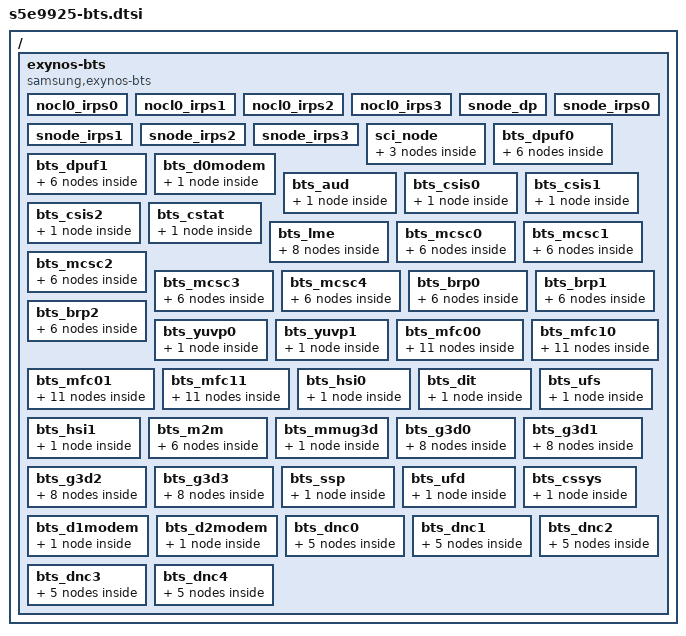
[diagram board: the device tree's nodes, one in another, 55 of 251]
/*
 * SAMSUNG EXYNOS SoC BTS device tree source
 *
 * Copyright (c) 2018 Samsung Electronics Co., Ltd.
 *		http://www.samsung.com
 *
 * SAMSUNG EXYNOS SoC BTS device nodes are listed in this file.
 * EXYNOS based board files should include this file.
 *
 * This program is free software; you can redistribute it and/or modify
 * it under the terms of the GNU General Public License version 2 as
 * published by the Free Software Foundation.
 *
 */

#include <dt-bindings/soc/samsung/exynos-bts.h>


/ {
	exynos-bts {
		compatible = "samsung,exynos-bts";
		#address-cells = <2>;
		#size-cells = <1>;
		ranges;

		list-scen = "default",
			"cp_throughput",
			"mfc_uhd",
			"mfc_uhd_10bit",
			"mfc_8k_dec30",
			"gdc_8k_8b_30",
			"gdc_8k_8b_60",
			"g3d_heavy",
			"g3d_performance",
			"dp_default",
			"camera_default",
			"npu_normal",
			"mfc_uhd_enc60",
			"camera_heavy",
			"npu_performance";

	        /* num_channel, mif_bus_width, bus_width, mif_util, int_util*/
	        bw_params = <4 16 32 65 70>;

		/* IRPS0/1/2/3 SCI_CTL_SCI_CTRL*/
		nocl0_irps0 {
			#address-cells = <2>;
			#size-cells = <1>;
			ranges;
			reg = <0x0 0x1A904000 0x400>;
			status = "okay";
			bts-type = <TREX_BTS>;
		};
		nocl0_irps1 {
			reg = <0x0 0x1A914000 0x400>;
			status = "okay";
			bts-type = <TREX_BTS>;
		};
		nocl0_irps2 {
			reg = <0x0 0x1A924000 0x400>;
			status = "okay";
			bts-type = <TREX_BTS>;
		};
		nocl0_irps3 {
			reg = <0x0 0x1A934000 0x400>;
			status = "okay";
			bts-type = <TREX_BTS>;
		};
		/* QMAX THRESHOLD */
		snode_dp {
			reg = <0x0 0x1A942000 0x100>;
			status = "okay";
			bts-type = <BUSC_BTS>;
		};
		snode_irps0 {
			reg = <0x0 0x1A902000 0x100>;
			status = "okay";
			bts-type = <BUSC_BTS>;
		};
		snode_irps1 {
			reg = <0x0 0x1A912000 0x100>;
			status = "okay";
			bts-type = <BUSC_BTS>;
		};
		snode_irps2 {
			reg = <0x0 0x1A922000 0x100>;
			status = "okay";
			bts-type = <BUSC_BTS>;
		};
		snode_irps3 {
			reg = <0x0 0x1A932000 0x100>;
			status = "okay";
			bts-type = <BUSC_BTS>;
		};
		sci_node {
			reg = <0x0 0x1A000100 0x100>;
			status = "okay";
			bts-type = <SCI_BTS>;
			default {
				stat_on = <1>;
				rmo = <0x0>;
				wmo = <0x0>;
			};
			camera_default {
				stat_on = <1>;
				rmo = <0x8>;
				wmo = <0x8>;
			};
			camera_heavy {
				stat_on = <1>;
				rmo = <0x8>;
				wmo = <0x8>;
			};
		};
		/* NOCL1A D0_DPUF0 */
		bts_dpuf0 {
			reg = <0x0 0x1B2A0000 0x100>;
			status = "okay";
			bts-type = <IP_BTS>;
			default {
				stat_on = <1>;
				bypass = <0>;
				arqos = <0x8>;
				awqos = <0x8>;
				qurgent_on = <0xC>;
				qurgent_th_r = <0x14>;
				blocking_on = <0>;
			};
			camera_default {
				stat_on = <1>;
				bypass = <0>;
				arqos = <0x8>;
				awqos = <0x8>;
				rmo = <0x20>;
				wmo = <0x20>;
				qurgent_on = <0>;
				blocking_on = <0>;
			};
			npu_normal {
				stat_on = <1>;
				bypass = <0>;
				arqos = <0x8>;
				awqos = <0x8>;
				rmo = <0x20>;
				wmo = <0x20>;
				qurgent_on = <0>;
				blocking_on = <0>;
			};
			mfc_uhd_enc60 {
				stat_on = <1>;
				bypass = <0>;
				arqos = <0x8>;
				awqos = <0x8>;
				rmo = <0x20>;
				wmo = <0x20>;
				qurgent_on = <0>;
				blocking_on = <0>;
			};
			camera_heavy {
				stat_on = <1>;
				bypass = <0>;
				arqos = <0x8>;
				awqos = <0x8>;
				rmo = <0x20>;
				wmo = <0x20>;
				qurgent_on = <0>;
				blocking_on = <0>;
			};
			npu_performance {
				stat_on = <1>;
				bypass = <0>;
				arqos = <0x8>;
				awqos = <0x8>;
				rmo = <0x20>;
				wmo = <0x20>;
				qurgent_on = <0>;
				blocking_on = <0>;
			};
		};
		/* NOCL1A D1_DPUF0 */
		bts_dpuf1 {
			reg = <0x0 0x1B2B0000 0x100>;
			status = "okay";
			bts-type = <IP_BTS>;
			default {
				stat_on = <1>;
				bypass = <0>;
				arqos = <0x8>;
				awqos = <0x8>;
				qurgent_on = <0xC>;
				qurgent_th_r = <0x14>;
				blocking_on = <0>;
			};
			camera_default {
				stat_on = <1>;
				bypass = <0>;
				arqos = <0x8>;
				awqos = <0x8>;
				rmo = <0x20>;
				wmo = <0x20>;
				qurgent_on = <0>;
				blocking_on = <0>;
			};
			npu_normal {
				stat_on = <1>;
				bypass = <0>;
				arqos = <0x8>;
				awqos = <0x8>;
				rmo = <0x20>;
				wmo = <0x20>;
				qurgent_on = <0>;
				blocking_on = <0>;
			};
			mfc_uhd_enc60 {
				stat_on = <1>;
				bypass = <0>;
				arqos = <0x8>;
				awqos = <0x8>;
				rmo = <0x20>;
				wmo = <0x20>;
				qurgent_on = <0>;
				blocking_on = <0>;
			};
			camera_heavy {
				stat_on = <1>;
				bypass = <0>;
				arqos = <0x8>;
				awqos = <0x8>;
				rmo = <0x20>;
				wmo = <0x20>;
				qurgent_on = <0>;
				blocking_on = <0>;
			};
			npu_performance {
				stat_on = <1>;
				bypass = <0>;
				arqos = <0x8>;
				awqos = <0x8>;
				rmo = <0x20>;
				wmo = <0x20>;
				qurgent_on = <0>;
				blocking_on = <0>;
			};
		};
		/* NOCL0 D0_MODEM */
		bts_d0modem {
			reg = <0x0 0x1A890000 0x100>;
			status = "okay";
			bts-type = <IP_BTS>;
			default {
				stat_on = <1>;
				bypass = <0>;
				arqos = <0xD>;
				awqos = <0xD>;
				rmo = <0x20>;
				wmo = <0x20>;
				qurgent_on = <0xC>;
				qurgent_th_r = <0x14>;
				qurgent_th_w = <0x14>;
				blocking_on = <0>;
			};
		};
		/* NOCL0 AUD */
		bts_aud {
			reg = <0x0 0x1A8C0000 0x100>;
			status = "okay";
			bts-type = <IP_BTS>;
			default {
				stat_on = <1>;
				bypass = <0>;
				arqos = <0x9>;
				awqos = <0x9>;
				qurgent_on = <0xC>;
				qurgent_th_r = <0x14>;
				qurgent_th_w = <0x14>;
				blocking_on = <0>;
			};
		};
		/* NOCL1C D0_CSIS */
		bts_csis0 {
			reg = <0x0 0x1B400000 0x100>;
			status = "okay";
			bts-type = <IP_BTS>;
			cal-pdid = <0xB1380002>;
			default {
				stat_on = <1>;
				bypass = <0>;
				arqos = <0xC>;
				awqos = <0xC>;
				qurgent_on = <0xC>;
				qurgent_th_r = <0x14>;
				qurgent_th_w = <0xD>;
				blocking_on = <0>;
			};
		};
		/* NOCL1C D1_CSIS */
		bts_csis1 {
			reg = <0x0 0x1B410000 0x100>;
			status = "okay";
			bts-type = <IP_BTS>;
			cal-pdid = <0xB1380002>;
			default {
				stat_on = <1>;
				bypass = <0>;
				arqos = <0xC>;
				awqos = <0xC>;
				qurgent_on = <0xC>;
				qurgent_th_r = <0x14>;
				qurgent_th_w = <0xD>;
				blocking_on = <0>;
			};
		};
		/* NOCL1C D2_CSIS */
		bts_csis2 {
			reg = <0x0 0x1B420000 0x100>;
			status = "okay";
			bts-type = <IP_BTS>;
			cal-pdid = <0xB1380002>;
			default {
				stat_on = <1>;
				bypass = <0>;
				arqos = <0xC>;
				awqos = <0xC>;
				qurgent_on = <0xC>;
				qurgent_th_r = <0x14>;
				qurgent_th_w = <0xD>;
				blocking_on = <0>;
			};
		};
		/* NOCL1C CSTAT */
		bts_cstat {
			reg = <0x0 0x1B430000 0x100>;
			status = "okay";
			bts-type = <IP_BTS>;
			cal-pdid = <0xB1380002>;
			default {
				stat_on = <1>;
				bypass = <0>;
				arqos = <0xC>;
				awqos = <0xC>;
				qurgent_on = <0xC>;
				qurgent_th_r = <0x14>;
				qurgent_th_w = <0xD>;
				blocking_on = <0>;
			};
		};
		/* NOCL1A LME */
		bts_lme {
			reg = <0x0 0x1B250000 0x100>;
			status = "okay";
			bts-type = <IP_BTS>;
			default {
				stat_on = <1>;
				bypass = <0>;
				arqos = <0x4>;
				awqos = <0x4>;
				rmo = <0x4>;
				wmo = <0x8>;
				qurgent_on = <0>;
				blocking_on = <0>;
			};
			gdc_8k_8b_30 {
				stat_on = <1>;
				bypass = <0>;
				arqos = <0x4>;
				awqos = <0x4>;
				rmo = <0x3C>;
				wmo = <0x14>;
				qurgent_on = <0>;
				blocking_on = <0>;
			};
			gdc_8k_8b_60 {
				stat_on = <1>;
				bypass = <0>;
				arqos = <0x4>;
				awqos = <0x4>;
				rmo = <0x84>;
				wmo = <0x28>;
				qurgent_on = <0>;
				blocking_on = <0>;
			};
			camera_default {
				stat_on = <1>;
				bypass = <0>;
				arqos = <0x4>;
				awqos = <0x4>;
				rmo = <0x28>;
				wmo = <0x8>;
				qurgent_on = <0>;
				blocking_on = <0>;
			};
			npu_normal {
				stat_on = <1>;
				bypass = <0>;
				arqos = <0x4>;
				awqos = <0x4>;
				rmo = <0x28>;
				wmo = <0x8>;
				qurgent_on = <0>;
				blocking_on = <0>;
			};
			mfc_uhd_enc60 {
				stat_on = <1>;
				bypass = <0>;
				arqos = <0x4>;
				awqos = <0x4>;
				rmo = <0x4>;
				wmo = <0x8>;
				qurgent_on = <0>;
				blocking_on = <0>;
			};
			camera_heavy {
				stat_on = <1>;
				bypass = <0>;
				arqos = <0x4>;
				awqos = <0x4>;
				rmo = <0x28>;
				wmo = <0x8>;
				qurgent_on = <0>;
				blocking_on = <0>;
			};
			npu_performance {
				stat_on = <1>;
				bypass = <0>;
				arqos = <0x4>;
				awqos = <0x4>;
				rmo = <0x4>;
				wmo = <0x8>;
				qurgent_on = <0>;
				blocking_on = <0>;
			};
		};
		/* NOCL1C D0_MCSC */
		bts_mcsc0 {
			reg = <0x0 0x1B470000 0x100>;
			status = "okay";
			bts-type = <IP_BTS>;
			cal-pdid = <0xB1380002>;
			default {
				stat_on = <1>;
				bypass = <0>;
				arqos = <0x4>;
				awqos = <0x4>;
				rmo = <0x8>;
				wmo = <0x8>;
				qurgent_on = <0>;
				blocking_on = <0>;
			};
			camera_default {
				stat_on = <1>;
				bypass = <0>;
				arqos = <0x4>;
				awqos = <0x4>;
				rmo = <0x10>;
				wmo = <0x8>;
				qurgent_on = <0>;
				blocking_on = <0>;
			};
			npu_normal {
				stat_on = <1>;
				bypass = <0>;
				arqos = <0x4>;
				awqos = <0x4>;
				rmo = <0x10>;
				wmo = <0x8>;
				qurgent_on = <0>;
				blocking_on = <0>;
			};
			mfc_uhd_enc60 {
				stat_on = <1>;
				bypass = <0>;
				arqos = <0x4>;
				awqos = <0x4>;
				rmo = <0x8>;
				wmo = <0x8>;
				qurgent_on = <0>;
				blocking_on = <0>;
			};
			camera_heavy {
				stat_on = <1>;
				bypass = <0>;
				arqos = <0x4>;
				awqos = <0x4>;
				rmo = <0x20>;
				wmo = <0x20>;
				qurgent_on = <0>;
				blocking_on = <0>;
			};
			npu_performance {
				stat_on = <1>;
				bypass = <0>;
				arqos = <0x4>;
				awqos = <0x4>;
				rmo = <0x8>;
				wmo = <0x8>;
				qurgent_on = <0>;
				blocking_on = <0>;
			};
		};
		/* NOCL1C D1_MCSC */
		bts_mcsc1 {
			reg = <0x0 0x1B480000 0x100>;
			status = "okay";
			bts-type = <IP_BTS>;
			cal-pdid = <0xB1380002>;
			default {
				stat_on = <1>;
				bypass = <0>;
				arqos = <0x4>;
				awqos = <0x4>;
				rmo = <0x8>;
				wmo = <0x8>;
				qurgent_on = <0>;
				blocking_on = <0>;
			};
			camera_default {
				stat_on = <1>;
				bypass = <0>;
				arqos = <0x4>;
				awqos = <0x4>;
				rmo = <0x10>;
				wmo = <0x10>;
				qurgent_on = <0>;
				blocking_on = <0>;
			};
			npu_normal {
				stat_on = <1>;
				bypass = <0>;
				arqos = <0x4>;
				awqos = <0x4>;
				rmo = <0x10>;
				wmo = <0x10>;
				qurgent_on = <0>;
				blocking_on = <0>;
			};
			mfc_uhd_enc60 {
				stat_on = <1>;
				bypass = <0>;
				arqos = <0x4>;
				awqos = <0x4>;
				rmo = <0x8>;
				wmo = <0x8>;
				qurgent_on = <0>;
				blocking_on = <0>;
			};
			camera_heavy {
				stat_on = <1>;
				bypass = <0>;
				arqos = <0x4>;
				awqos = <0x4>;
				rmo = <0x20>;
				wmo = <0x20>;
				qurgent_on = <0>;
				blocking_on = <0>;
			};
			npu_performance {
				stat_on = <1>;
				bypass = <0>;
				arqos = <0x4>;
				awqos = <0x4>;
				rmo = <0x8>;
				wmo = <0x8>;
				qurgent_on = <0>;
				blocking_on = <0>;
			};
		};
		/* NOCL1C D2_MCSC */
		bts_mcsc2 {
			reg = <0x0 0x1B490000 0x100>;
			status = "okay";
			bts-type = <IP_BTS>;
			cal-pdid = <0xB1380002>;
			default {
				stat_on = <1>;
				bypass = <0>;
				arqos = <0x4>;
				awqos = <0x4>;
				rmo = <0x8>;
				wmo = <0x8>;
				qurgent_on = <0>;
				blocking_on = <0>;
			};
			camera_default {
				stat_on = <1>;
				bypass = <0>;
				arqos = <0x4>;
				awqos = <0x4>;
				rmo = <0x10>;
				wmo = <0x10>;
				qurgent_on = <0>;
				blocking_on = <0>;
			};
			npu_normal {
				stat_on = <1>;
				bypass = <0>;
				arqos = <0x4>;
				awqos = <0x4>;
				rmo = <0x10>;
				wmo = <0x10>;
				qurgent_on = <0>;
				blocking_on = <0>;
			};
			mfc_uhd_enc60 {
				stat_on = <1>;
				bypass = <0>;
				arqos = <0x4>;
				awqos = <0x4>;
				rmo = <0x8>;
				wmo = <0x8>;
				qurgent_on = <0>;
				blocking_on = <0>;
			};
			camera_heavy {
				stat_on = <1>;
				bypass = <0>;
				arqos = <0x4>;
				awqos = <0x4>;
				rmo = <0x20>;
				wmo = <0x20>;
				qurgent_on = <0>;
				blocking_on = <0>;
			};
			npu_performance {
				stat_on = <1>;
				bypass = <0>;
				arqos = <0x4>;
				awqos = <0x4>;
				rmo = <0x8>;
				wmo = <0x8>;
				qurgent_on = <0>;
				blocking_on = <0>;
			};
		};
		/* NOCL1C D3_MCSC */
		bts_mcsc3 {
			reg = <0x0 0x1B4A0000 0x100>;
			status = "okay";
			bts-type = <IP_BTS>;
			cal-pdid = <0xB1380002>;
			default {
				stat_on = <1>;
				bypass = <0>;
				arqos = <0x4>;
				awqos = <0x4>;
				rmo = <0x8>;
				wmo = <0x8>;
				qurgent_on = <0>;
				blocking_on = <0>;
			};
			camera_default {
				stat_on = <1>;
				bypass = <0>;
				arqos = <0x4>;
				awqos = <0x4>;
				rmo = <0x10>;
				wmo = <0x10>;
				qurgent_on = <0>;
				blocking_on = <0>;
			};
			npu_normal {
				stat_on = <1>;
				bypass = <0>;
				arqos = <0x4>;
				awqos = <0x4>;
				rmo = <0x10>;
				wmo = <0x10>;
				qurgent_on = <0>;
				blocking_on = <0>;
			};
			mfc_uhd_enc60 {
				stat_on = <1>;
				bypass = <0>;
				arqos = <0x4>;
				awqos = <0x4>;
				rmo = <0x8>;
				wmo = <0x8>;
				qurgent_on = <0>;
				blocking_on = <0>;
			};
			camera_heavy {
				stat_on = <1>;
				bypass = <0>;
				arqos = <0x4>;
				awqos = <0x4>;
				rmo = <0x20>;
				wmo = <0x20>;
				qurgent_on = <0>;
				blocking_on = <0>;
			};
			npu_performance {
				stat_on = <1>;
				bypass = <0>;
				arqos = <0x4>;
				awqos = <0x4>;
				rmo = <0x8>;
				wmo = <0x8>;
				qurgent_on = <0>;
				blocking_on = <0>;
			};
		};
		/* NOCL1C D4_MCSC */
		bts_mcsc4 {
			reg = <0x0 0x1B4B0000 0x100>;
			status = "okay";
			bts-type = <IP_BTS>;
			cal-pdid = <0xB1380002>;
			default {
				stat_on = <1>;
				bypass = <0>;
				arqos = <0x4>;
				awqos = <0x4>;
				rmo = <0x8>;
				wmo = <0x8>;
				qurgent_on = <0>;
				blocking_on = <0>;
			};
			camera_default {
				stat_on = <1>;
				bypass = <0>;
				arqos = <0x4>;
				awqos = <0x4>;
				rmo = <0x10>;
				wmo = <0x10>;
				qurgent_on = <0>;
				blocking_on = <0>;
			};
			npu_normal {
				stat_on = <1>;
				bypass = <0>;
				arqos = <0x4>;
				awqos = <0x4>;
				rmo = <0x10>;
				wmo = <0x10>;
				qurgent_on = <0>;
				blocking_on = <0>;
			};
			mfc_uhd_enc60 {
				stat_on = <1>;
				bypass = <0>;
				arqos = <0x4>;
				awqos = <0x4>;
				rmo = <0x8>;
				wmo = <0x8>;
				qurgent_on = <0>;
				blocking_on = <0>;
			};
			camera_heavy {
				stat_on = <1>;
				bypass = <0>;
				arqos = <0x4>;
				awqos = <0x4>;
				rmo = <0x20>;
				wmo = <0x20>;
				qurgent_on = <0>;
				blocking_on = <0>;
			};
			npu_performance {
				stat_on = <1>;
				bypass = <0>;
				arqos = <0x4>;
				awqos = <0x4>;
				rmo = <0x8>;
				wmo = <0x8>;
				qurgent_on = <0>;
				blocking_on = <0>;
			};
		};
		/* NOCL1C D0_BRP */
		bts_brp0 {
			reg = <0x0 0x1B440000 0x100>;
			status = "okay";
			bts-type = <IP_BTS>;
			cal-pdid = <0xB1380002>;
			default {
				stat_on = <1>;
				bypass = <0>;
				arqos = <0x4>;
				awqos = <0x4>;
				rmo = <0x4>;
				wmo = <0x8>;
				qurgent_on = <0>;
				blocking_on = <0>;
			};
			camera_default {
				stat_on = <1>;
				bypass = <0>;
				arqos = <0x4>;
				awqos = <0x4>;
				rmo = <0x10>;
				wmo = <0x8>;
				qurgent_on = <0>;
				blocking_on = <0>;
			};
			npu_normal {
				stat_on = <1>;
				bypass = <0>;
				arqos = <0x4>;
				awqos = <0x4>;
				rmo = <0x10>;
				wmo = <0x8>;
				qurgent_on = <0>;
				blocking_on = <0>;
			};
			mfc_uhd_enc60 {
				stat_on = <1>;
				bypass = <0>;
				arqos = <0x4>;
				awqos = <0x4>;
				rmo = <0x4>;
				wmo = <0x8>;
				qurgent_on = <0>;
				blocking_on = <0>;
			};
			camera_heavy {
				stat_on = <1>;
				bypass = <0>;
				arqos = <0x4>;
				awqos = <0x4>;
				rmo = <0x20>;
				wmo = <0x20>;
				qurgent_on = <0>;
				blocking_on = <0>;
			};
			npu_performance {
				stat_on = <1>;
				bypass = <0>;
				arqos = <0x4>;
				awqos = <0x4>;
				rmo = <0x4>;
				wmo = <0x8>;
				qurgent_on = <0>;
				blocking_on = <0>;
			};

		};
		/* NOCL1C D1_BRP */
		bts_brp1 {
			reg = <0x0 0x1B450000 0x100>;
			status = "okay";
			bts-type = <IP_BTS>;
			cal-pdid = <0xB1380002>;
			default {
				stat_on = <1>;
				bypass = <0>;
				arqos = <0x4>;
				awqos = <0x4>;
				rmo = <0x4>;
				wmo = <0x8>;
				qurgent_on = <0>;
				blocking_on = <0>;
			};
			camera_default {
				stat_on = <1>;
				bypass = <0>;
				arqos = <0x4>;
				awqos = <0x4>;
				rmo = <0x10>;
				wmo = <0x8>;
				qurgent_on = <0>;
				blocking_on = <0>;
			};
			npu_normal {
				stat_on = <1>;
				bypass = <0>;
				arqos = <0x4>;
				awqos = <0x4>;
				rmo = <0x10>;
				wmo = <0x8>;
				qurgent_on = <0>;
				blocking_on = <0>;
			};
			mfc_uhd_enc60 {
				stat_on = <1>;
				bypass = <0>;
				arqos = <0x4>;
				awqos = <0x4>;
				rmo = <0x4>;
				wmo = <0x8>;
				qurgent_on = <0>;
				blocking_on = <0>;
			};
			camera_heavy {
				stat_on = <1>;
				bypass = <0>;
				arqos = <0x4>;
				awqos = <0x4>;
				rmo = <0x20>;
				wmo = <0x20>;
				qurgent_on = <0>;
				blocking_on = <0>;
			};
			npu_performance {
				stat_on = <1>;
				bypass = <0>;
				arqos = <0x4>;
				awqos = <0x4>;
				rmo = <0x4>;
				wmo = <0x8>;
				qurgent_on = <0>;
				blocking_on = <0>;
			};

		};
		/* NOCL1C D2_BRP */
		bts_brp2 {
			reg = <0x0 0x1B460000 0x100>;
			status = "okay";
			bts-type = <IP_BTS>;
			cal-pdid = <0xB1380002>;
			default {
				stat_on = <1>;
				bypass = <0>;
				arqos = <0x4>;
				awqos = <0x4>;
				rmo = <0x4>;
				wmo = <0x8>;
				qurgent_on = <0>;
				blocking_on = <0>;
			};
			camera_default {
				stat_on = <1>;
				bypass = <0>;
				arqos = <0x4>;
				awqos = <0x4>;
				rmo = <0x10>;
				wmo = <0x8>;
				qurgent_on = <0>;
				blocking_on = <0>;
			};
			npu_normal {
				stat_on = <1>;
				bypass = <0>;
				arqos = <0x4>;
				awqos = <0x4>;
				rmo = <0x10>;
				wmo = <0x8>;
				qurgent_on = <0>;
				blocking_on = <0>;
			};
			mfc_uhd_enc60 {
				stat_on = <1>;
				bypass = <0>;
				arqos = <0x4>;
				awqos = <0x4>;
				rmo = <0x4>;
				wmo = <0x8>;
				qurgent_on = <0>;
				blocking_on = <0>;
			};
			camera_heavy {
				stat_on = <1>;
				bypass = <0>;
				arqos = <0x4>;
				awqos = <0x4>;
				rmo = <0x20>;
				wmo = <0x20>;
				qurgent_on = <0>;
				blocking_on = <0>;
			};
			npu_performance {
				stat_on = <1>;
				bypass = <0>;
				arqos = <0x4>;
				awqos = <0x4>;
				rmo = <0x4>;
				wmo = <0x8>;
				qurgent_on = <0>;
				blocking_on = <0>;
			};

		};
		/* NOCL1C YUVP0 */
		bts_yuvp0 {
			reg = <0x0 0x1B4C0000 0x100>;
			status = "okay";
			bts-type = <IP_BTS>;
			cal-pdid = <0xB1380002>;
			default {
				stat_on = <1>;
				bypass = <0>;
				arqos = <0x4>;
				awqos = <0x4>;
				rmo = <0xC>;
				wmo = <0xC>;
				qurgent_on = <0>;
				blocking_on = <0>;
			};
		};
		/* NOCL1C YUVP1 */
		bts_yuvp1 {
			reg = <0x0 0x1B4D0000 0x100>;
			status = "okay";
			bts-type = <IP_BTS>;
			cal-pdid = <0xB1380002>;
			default {
				stat_on = <1>;
				bypass = <0>;
				arqos = <0x4>;
				awqos = <0x4>;
				rmo = <0xC>;
				wmo = <0xC>;
				qurgent_on = <0>;
				blocking_on = <0>;
			};
		};
		/* NOCL1A D0_MFC0 */
		bts_mfc00 {
			reg = <0x0 0x1B260000 0x100>;
			status = "okay";
			bts-type = <IP_BTS>;
			default {
				stat_on = <1>;
				bypass = <0>;
				arqos = <0x4>;
				awqos = <0x4>;
				rmo = <0x1C>;
				wmo = <0xC>;
				qurgent_on = <0>;
				blocking_on = <0>;
			};
			mfc_uhd {
				stat_on = <1>;
				bypass = <0>;
				arqos = <0x4>;
				awqos = <0x4>;
				rmo = <0x20>;
				wmo = <0x20>;
				qurgent_on = <0>;
				blocking_on = <0>;
			};
			mfc_uhd_10bit {
				stat_on = <1>;
				bypass = <0>;
				arqos = <0x4>;
				awqos = <0x4>;
				rmo = <0x20>;
				wmo = <0x20>;
				qurgent_on = <0>;
				blocking_on = <0>;
			};
			mfc_8k_dec30 {
				stat_on = <1>;
				bypass = <0>;
				arqos = <0x4>;
				awqos = <0x4>;
				rmo = <0x40>;
				wmo = <0x40>;
				qurgent_on = <0>;
				blocking_on = <0>;
			};
			g3d_performance {
				stat_on = <1>;
				bypass = <0>;
				arqos = <0x4>;
				awqos = <0x4>;
				rmo = <0x20>;
				wmo = <0x20>;
				qurgent_on = <0>;
				blocking_on = <0>;
			};
			dp_default {
				stat_on = <1>;
				bypass = <0>;
				arqos = <0x4>;
				awqos = <0x4>;
				rmo = <0x20>;
				wmo = <0x20>;
				qurgent_on = <0>;
				blocking_on = <0>;
			};
			camera_default {
				stat_on = <1>;
				bypass = <0>;
				arqos = <0x4>;
				awqos = <0x4>;
				rmo = <0x1C>;
				wmo = <0xC>;
				qurgent_on = <0>;
				blocking_on = <0>;
			};
			npu_normal {
				stat_on = <1>;
				bypass = <0>;
				arqos = <0x4>;
				awqos = <0x4>;
				rmo = <0x1C>;
				wmo = <0xC>;
				qurgent_on = <0>;
				blocking_on = <0>;
			};
			mfc_uhd_enc60 {
				stat_on = <1>;
				bypass = <0>;
				arqos = <0x4>;
				awqos = <0x4>;
				rmo = <0x20>;
				wmo = <0x20>;
				qurgent_on = <0>;
				blocking_on = <0>;
			};
			camera_heavy {
				stat_on = <1>;
				bypass = <0>;
				arqos = <0x4>;
				awqos = <0x4>;
				rmo = <0x1C>;
				wmo = <0xC>;
				qurgent_on = <0>;
				blocking_on = <0>;
			};
			npu_performance {
				stat_on = <1>;
				bypass = <0>;
				arqos = <0x4>;
				awqos = <0x4>;
				rmo = <0x1C>;
				wmo = <0xC>;
				qurgent_on = <0>;
				blocking_on = <0>;
			};
		};
		/* NOCL1A D0_MFC1 */
		bts_mfc10 {
			reg = <0x0 0x1B280000 0x100>;
			status = "okay";
			bts-type = <IP_BTS>;
			default {
				stat_on = <1>;
				bypass = <0>;
				arqos = <0x4>;
				awqos = <0x4>;
				rmo = <0x1C>;
				wmo = <0xC>;
				qurgent_on = <0>;
				blocking_on = <0>;
			};
			mfc_uhd {
				stat_on = <1>;
				bypass = <0>;
				arqos = <0x4>;
				awqos = <0x4>;
				rmo = <0x20>;
				wmo = <0x20>;
				qurgent_on = <0>;
				blocking_on = <0>;
			};
			mfc_uhd_10bit {
				stat_on = <1>;
				bypass = <0>;
				arqos = <0x4>;
				awqos = <0x4>;
				rmo = <0x20>;
				wmo = <0x20>;
				qurgent_on = <0>;
				blocking_on = <0>;
			};
			mfc_8k_dec30 {
				stat_on = <1>;
				bypass = <0>;
				arqos = <0x4>;
				awqos = <0x4>;
				rmo = <0x40>;
				wmo = <0x40>;
				qurgent_on = <0>;
				blocking_on = <0>;
			};
			g3d_performance {
				stat_on = <1>;
				bypass = <0>;
				arqos = <0x4>;
				awqos = <0x4>;
				rmo = <0x20>;
				wmo = <0x20>;
				qurgent_on = <0>;
				blocking_on = <0>;
			};
			dp_default {
				stat_on = <1>;
				bypass = <0>;
				arqos = <0x4>;
				awqos = <0x4>;
				rmo = <0x20>;
				wmo = <0x20>;
				qurgent_on = <0>;
				blocking_on = <0>;
			};
			camera_default {
				stat_on = <1>;
				bypass = <0>;
				arqos = <0x4>;
				awqos = <0x4>;
				rmo = <0x1C>;
				wmo = <0xC>;
				qurgent_on = <0>;
				blocking_on = <0>;
			};
			npu_normal {
				stat_on = <1>;
				bypass = <0>;
				arqos = <0x4>;
				awqos = <0x4>;
				rmo = <0x1C>;
				wmo = <0xC>;
				qurgent_on = <0>;
				blocking_on = <0>;
			};
			mfc_uhd_enc60 {
				stat_on = <1>;
				bypass = <0>;
				arqos = <0x4>;
				awqos = <0x4>;
				rmo = <0x20>;
				wmo = <0x20>;
				qurgent_on = <0>;
				blocking_on = <0>;
			};
			camera_heavy {
				stat_on = <1>;
				bypass = <0>;
				arqos = <0x4>;
				awqos = <0x4>;
				rmo = <0x1C>;
				wmo = <0xC>;
				qurgent_on = <0>;
				blocking_on = <0>;
			};
			npu_performance {
				stat_on = <1>;
				bypass = <0>;
				arqos = <0x4>;
				awqos = <0x4>;
				rmo = <0x1C>;
				wmo = <0xC>;
				qurgent_on = <0>;
				blocking_on = <0>;
			};
		};
		/* NOCL1A D1_MFC0 */
		bts_mfc01 {
			reg = <0x0 0x1B270000 0x100>;
			status = "okay";
			bts-type = <IP_BTS>;
			default {
				stat_on = <1>;
				bypass = <0>;
				arqos = <0x4>;
				awqos = <0x4>;
				rmo = <0x1C>;
				wmo = <0xC>;
				qurgent_on = <0>;
				blocking_on = <0>;
			};
			mfc_uhd {
				stat_on = <1>;
				bypass = <0>;
				arqos = <0x4>;
				awqos = <0x4>;
				rmo = <0x20>;
				wmo = <0x20>;
				qurgent_on = <0>;
				blocking_on = <0>;
			};
			mfc_uhd_10bit {
				stat_on = <1>;
				bypass = <0>;
				arqos = <0x4>;
				awqos = <0x4>;
				rmo = <0x20>;
				wmo = <0x20>;
				qurgent_on = <0>;
				blocking_on = <0>;
			};
			mfc_8k_dec30 {
				stat_on = <1>;
				bypass = <0>;
				arqos = <0x4>;
				awqos = <0x4>;
				rmo = <0x40>;
				wmo = <0x40>;
				qurgent_on = <0>;
				blocking_on = <0>;
			};
			g3d_performance {
				stat_on = <1>;
				bypass = <0>;
				arqos = <0x4>;
				awqos = <0x4>;
				rmo = <0x20>;
				wmo = <0x20>;
				qurgent_on = <0>;
				blocking_on = <0>;
			};
			dp_default {
				stat_on = <1>;
				bypass = <0>;
				arqos = <0x4>;
				awqos = <0x4>;
				rmo = <0x20>;
				wmo = <0x20>;
				qurgent_on = <0>;
				blocking_on = <0>;
			};
			camera_default {
				stat_on = <1>;
				bypass = <0>;
				arqos = <0x4>;
				awqos = <0x4>;
				rmo = <0x1C>;
				wmo = <0xC>;
				qurgent_on = <0>;
				blocking_on = <0>;
			};
			npu_normal {
				stat_on = <1>;
				bypass = <0>;
				arqos = <0x4>;
				awqos = <0x4>;
				rmo = <0x1C>;
				wmo = <0xC>;
				qurgent_on = <0>;
				blocking_on = <0>;
			};
			mfc_uhd_enc60 {
				stat_on = <1>;
				bypass = <0>;
				arqos = <0x4>;
				awqos = <0x4>;
				rmo = <0x20>;
				wmo = <0x20>;
				qurgent_on = <0>;
				blocking_on = <0>;
			};
			camera_heavy {
				stat_on = <1>;
				bypass = <0>;
				arqos = <0x4>;
				awqos = <0x4>;
				rmo = <0x1C>;
				wmo = <0xC>;
				qurgent_on = <0>;
				blocking_on = <0>;
			};
			npu_performance {
				stat_on = <1>;
				bypass = <0>;
				arqos = <0x4>;
				awqos = <0x4>;
				rmo = <0x1C>;
				wmo = <0xC>;
				qurgent_on = <0>;
				blocking_on = <0>;
			};
		};
		/* NOCL1A D1_MFC1 */
		bts_mfc11 {
			reg = <0x0 0x1B290000 0x100>;
			status = "okay";
			bts-type = <IP_BTS>;
			default {
				stat_on = <1>;
				bypass = <0>;
				arqos = <0x4>;
				awqos = <0x4>;
				rmo = <0x1C>;
				wmo = <0xC>;
				qurgent_on = <0>;
				blocking_on = <0>;
			};
			mfc_uhd {
				stat_on = <1>;
				bypass = <0>;
				arqos = <0x4>;
				awqos = <0x4>;
				rmo = <0x20>;
				wmo = <0x20>;
				qurgent_on = <0>;
				blocking_on = <0>;
			};
			mfc_uhd_10bit {
				stat_on = <1>;
				bypass = <0>;
				arqos = <0x4>;
				awqos = <0x4>;
				rmo = <0x20>;
				wmo = <0x20>;
				qurgent_on = <0>;
				blocking_on = <0>;
			};
			mfc_8k_dec30 {
				stat_on = <1>;
				bypass = <0>;
				arqos = <0x4>;
				awqos = <0x4>;
				rmo = <0x40>;
				wmo = <0x40>;
				qurgent_on = <0>;
				blocking_on = <0>;
			};
			g3d_performance {
				stat_on = <1>;
				bypass = <0>;
				arqos = <0x4>;
				awqos = <0x4>;
				rmo = <0x20>;
				wmo = <0x20>;
				qurgent_on = <0>;
				blocking_on = <0>;
			};
			dp_default {
				stat_on = <1>;
				bypass = <0>;
				arqos = <0x4>;
				awqos = <0x4>;
				rmo = <0x20>;
				wmo = <0x20>;
				qurgent_on = <0>;
				blocking_on = <0>;
			};
			camera_default {
				stat_on = <1>;
				bypass = <0>;
				arqos = <0x4>;
				awqos = <0x4>;
				rmo = <0x1C>;
				wmo = <0xC>;
				qurgent_on = <0>;
				blocking_on = <0>;
			};
			npu_normal {
				stat_on = <1>;
				bypass = <0>;
				arqos = <0x4>;
				awqos = <0x4>;
				rmo = <0x1C>;
				wmo = <0xC>;
				qurgent_on = <0>;
				blocking_on = <0>;
			};
			mfc_uhd_enc60 {
				stat_on = <1>;
				bypass = <0>;
				arqos = <0x4>;
				awqos = <0x4>;
				rmo = <0x20>;
				wmo = <0x20>;
				qurgent_on = <0>;
				blocking_on = <0>;
			};
			camera_heavy {
				stat_on = <1>;
				bypass = <0>;
				arqos = <0x4>;
				awqos = <0x4>;
				rmo = <0x1C>;
				wmo = <0xC>;
				qurgent_on = <0>;
				blocking_on = <0>;
			};
			npu_performance {
				stat_on = <1>;
				bypass = <0>;
				arqos = <0x4>;
				awqos = <0x4>;
				rmo = <0x1C>;
				wmo = <0xC>;
				qurgent_on = <0>;
				blocking_on = <0>;
			};
		};
		/* NOCL1B HSI0 */
		bts_hsi0 {
			reg = <0x0 0x1B000000 0x100>;
			status = "okay";
			bts-type = <IP_BTS>;
			default {
				stat_on = <1>;
				bypass = <0>;
				arqos = <0x4>;
				awqos = <0x4>;
				rmo = <0x4>;
				wmo = <0x4>;
				qurgent_on = <0>;
				blocking_on = <1>;
				qmax0_limit_r = <0x1>;
				qmax0_limit_w = <0x1>;
			};
		};
		/* NOCL1B DIT */
		bts_dit {
			reg = <0x0 0x1B030000 0x100>;
			status = "okay";
			bts-type = <IP_BTS>;
			default {
				stat_on = <1>;
				bypass = <0>;
				arqos = <0x4>;
				awqos = <0x4>;
				rmo = <0x4>;
				wmo = <0x4>;
				qurgent_on = <0>;
				blocking_on = <1>;
				qmax0_limit_r = <0x1>;
				qmax0_limit_w = <0x1>;
			};
		};
		/* NOCL1B ufs */
		bts_ufs {
			reg = <0x0 0x1B010000 0x100>;
			status = "okay";
			bts-type = <IP_BTS>;
			default {
				stat_on = <1>;
				bypass = <0>;
				arqos = <0x4>;
				awqos = <0x4>;
				rmo = <0x4>;
				wmo = <0x4>;
				qurgent_on = <0>;
				blocking_on = <1>;
				qmax0_limit_r = <0x1>;
				qmax0_limit_w = <0x1>;
			};
		};
		/* NOCL1A HSI1 */
		bts_hsi1 {
			reg = <0x0 0x1B240000 0x100>;
			status = "okay";
			bts-type = <IP_BTS>;
			default {
				stat_on = <1>;
				bypass = <0>;
				arqos = <0x4>;
				awqos = <0x4>;
				rmo = <0x4>;
				wmo = <0x4>;
				qurgent_on = <0>;
				blocking_on = <1>;
				qmax0_limit_r = <0x1>;
				qmax0_limit_w = <0x1>;
			};
		};
		/* NOCL1A M2M */
		bts_m2m {
			reg = <0x0 0x1B2C0000 0x100>;
			status = "okay";
			bts-type = <IP_BTS>;
			default {
				stat_on = <1>;
				bypass = <0>;
				arqos = <0x4>;
				awqos = <0x4>;
				rmo = <0x18>;
				wmo = <0x18>;
				qurgent_on = <0>;
				blocking_on = <1>;
				qmax0_limit_r = <0x8>;
				qmax0_limit_w = <0x8>;
			};
			camera_default {
				stat_on = <1>;
				bypass = <0>;
				arqos = <0x4>;
				awqos = <0x4>;
				rmo = <0x8>;
				wmo = <0x8>;
				qurgent_on = <0>;
				blocking_on = <0>;
			};
			npu_normal {
				stat_on = <1>;
				bypass = <0>;
				arqos = <0x4>;
				awqos = <0x4>;
				rmo = <0x8>;
				wmo = <0x8>;
				qurgent_on = <0>;
				blocking_on = <0>;
			};
			mfc_uhd_enc60 {
				stat_on = <1>;
				bypass = <0>;
				arqos = <0x4>;
				awqos = <0x4>;
				rmo = <0x8>;
				wmo = <0x8>;
				qurgent_on = <0>;
				blocking_on = <0>;
			};
			camera_heavy {
				stat_on = <1>;
				bypass = <0>;
				arqos = <0x4>;
				awqos = <0x4>;
				rmo = <0x20>;
				wmo = <0x20>;
				qurgent_on = <0>;
				blocking_on = <0>;
			};
			npu_performance {
				stat_on = <1>;
				bypass = <0>;
				arqos = <0x4>;
				awqos = <0x4>;
				rmo = <0x8>;
				wmo = <0x8>;
				qurgent_on = <0>;
				blocking_on = <0>;
			};
		};
		/* NOCL0 MMUG3D */
		bts_mmug3d {
			reg = <0x0 0x1A870000 0x100>;
			status = "okay";
			bts-type = <IP_BTS>;
			default {
				stat_on = <1>;
				bypass = <0>;
				arqos = <0x4>;
				awqos = <0x4>;
				rmo = <0x4>;
				wmo = <0x4>;
				qurgent_on = <0>;
				blocking_on = <0>;
			};
		};
		/* G3D CRPControl for MO and SYSREG_NOCL for QoS */
		bts_g3d0 {
			reg = <0x0 0x1A000010 0x20>,	/* for MO */
			    <0x0 0x1A021220 0x10>;	/* for QoS */
			status = "okay";
			bts-type = <SCI_GPU_BTS>;
			default {
				stat_on = <1>;
				bypass = <0>;
				arqos = <0x0>;
				awqos = <0x0>;
				rmo = <0x10>;
				wmo = <0x10>;
			};
			g3d_heavy {
				stat_on = <1>;
				bypass = <0>;
				arqos = <0x0>;
				awqos = <0x0>;
				rmo = <0x40>;
				wmo = <0x40>;
			};
			g3d_performance {
				stat_on = <1>;
				bypass = <0>;
				arqos = <0x0>;
				awqos = <0x0>;
				rmo = <0x40>;
				wmo = <0x40>;
			};
			camera_default {
				stat_on = <1>;
				bypass = <0>;
				arqos = <0x0>;
				awqos = <0x0>;
				rmo = <0x8>;
				wmo = <0x8>;
			};
			npu_normal {
				stat_on = <1>;
				bypass = <0>;
				arqos = <0x0>;
				awqos = <0x0>;
				rmo = <0x8>;
				wmo = <0x8>;
			};
			mfc_uhd_enc60 {
				stat_on = <1>;
				bypass = <0>;
				arqos = <0x0>;
				awqos = <0x0>;
				rmo = <0x8>;
				wmo = <0x8>;
			};
			camera_heavy {
				stat_on = <1>;
				bypass = <0>;
				arqos = <0x0>;
				awqos = <0x0>;
				rmo = <0x8>;
				wmo = <0x8>;
			};
			npu_performance {
				stat_on = <1>;
				bypass = <0>;
				arqos = <0x0>;
				awqos = <0x0>;
				rmo = <0x20>;
				wmo = <0x20>;
			};
		};
		bts_g3d1 {
			reg = <0x0 0x1A000038 0x20>,	/* for MO */
			    <0x0 0x1A021230 0x10>;	/* for QoS */
			status = "okay";
			bts-type = <SCI_GPU_BTS>;
			default {
				stat_on = <1>;
				bypass = <0>;
				arqos = <0x0>;
				awqos = <0x0>;
				rmo = <0x10>;
				wmo = <0x10>;
			};
			g3d_heavy {
				stat_on = <1>;
				bypass = <0>;
				arqos = <0x0>;
				awqos = <0x0>;
				rmo = <0x40>;
				wmo = <0x40>;
			};
			g3d_performance {
				stat_on = <1>;
				bypass = <0>;
				arqos = <0x0>;
				awqos = <0x0>;
				rmo = <0x40>;
				wmo = <0x40>;
			};
			camera_default {
				stat_on = <1>;
				bypass = <0>;
				arqos = <0x0>;
				awqos = <0x0>;
				rmo = <0x8>;
				wmo = <0x8>;
			};
			npu_normal {
				stat_on = <1>;
				bypass = <0>;
				arqos = <0x0>;
				awqos = <0x0>;
				rmo = <0x8>;
				wmo = <0x8>;
			};
			mfc_uhd_enc60 {
				stat_on = <1>;
				bypass = <0>;
				arqos = <0x0>;
				awqos = <0x0>;
				rmo = <0x8>;
				wmo = <0x8>;
			};
			camera_heavy {
				stat_on = <1>;
				bypass = <0>;
				arqos = <0x0>;
				awqos = <0x0>;
				rmo = <0x8>;
				wmo = <0x8>;
			};
			npu_performance {
				stat_on = <1>;
				bypass = <0>;
				arqos = <0x0>;
				awqos = <0x0>;
				rmo = <0x20>;
				wmo = <0x20>;
			};
		};
		bts_g3d2 {
			reg = <0x0 0x1A000060 0x20>,	/* for MO */
			    <0x0 0x1A021240 0x10>;	/* for QoS */
			status = "okay";
			bts-type = <SCI_GPU_BTS>;
			default {
				stat_on = <1>;
				bypass = <0>;
				arqos = <0x0>;
				awqos = <0x0>;
				rmo = <0x10>;
				wmo = <0x10>;
			};
			g3d_heavy {
				stat_on = <1>;
				bypass = <0>;
				arqos = <0x0>;
				awqos = <0x0>;
				rmo = <0x40>;
				wmo = <0x40>;
			};
			g3d_performance {
				stat_on = <1>;
				bypass = <0>;
				arqos = <0x0>;
				awqos = <0x0>;
				rmo = <0x40>;
				wmo = <0x40>;
			};
			camera_default {
				stat_on = <1>;
				bypass = <0>;
				arqos = <0x0>;
				awqos = <0x0>;
				rmo = <0x8>;
				wmo = <0x8>;
			};
			npu_normal {
				stat_on = <1>;
				bypass = <0>;
				arqos = <0x0>;
				awqos = <0x0>;
				rmo = <0x8>;
				wmo = <0x8>;
			};
			mfc_uhd_enc60 {
				stat_on = <1>;
				bypass = <0>;
				arqos = <0x0>;
				awqos = <0x0>;
				rmo = <0x8>;
				wmo = <0x8>;
			};
			camera_heavy {
				stat_on = <1>;
				bypass = <0>;
				arqos = <0x0>;
				awqos = <0x0>;
				rmo = <0x8>;
				wmo = <0x8>;
			};
			npu_performance {
				stat_on = <1>;
				bypass = <0>;
				arqos = <0x0>;
				awqos = <0x0>;
				rmo = <0x20>;
				wmo = <0x20>;
			};
		};
		bts_g3d3 {
			reg = <0x0 0x1A000088 0x20>,	/* for MO */
			    <0x0 0x1A021250 0x10>;	/* for QoS */
			status = "okay";
			bts-type = <SCI_GPU_BTS>;
			default {
				stat_on = <1>;
				bypass = <0>;
				arqos = <0x0>;
				awqos = <0x0>;
				rmo = <0x10>;
				wmo = <0x10>;
			};
			g3d_heavy {
				stat_on = <1>;
				bypass = <0>;
				arqos = <0x0>;
				awqos = <0x0>;
				rmo = <0x40>;
				wmo = <0x40>;
			};
			g3d_performance {
				stat_on = <1>;
				bypass = <0>;
				arqos = <0x0>;
				awqos = <0x0>;
				rmo = <0x40>;
				wmo = <0x40>;
			};
			camera_default {
				stat_on = <1>;
				bypass = <0>;
				arqos = <0x0>;
				awqos = <0x0>;
				rmo = <0x8>;
				wmo = <0x8>;
			};
			npu_normal {
				stat_on = <1>;
				bypass = <0>;
				arqos = <0x0>;
				awqos = <0x0>;
				rmo = <0x8>;
				wmo = <0x8>;
			};
			mfc_uhd_enc60 {
				stat_on = <1>;
				bypass = <0>;
				arqos = <0x0>;
				awqos = <0x0>;
				rmo = <0x8>;
				wmo = <0x8>;
			};
			camera_heavy {
				stat_on = <1>;
				bypass = <0>;
				arqos = <0x0>;
				awqos = <0x0>;
				rmo = <0x8>;
				wmo = <0x8>;
			};
			npu_performance {
				stat_on = <1>;
				bypass = <0>;
				arqos = <0x0>;
				awqos = <0x0>;
				rmo = <0x20>;
				wmo = <0x20>;
			};
		};
		/* NOCL0 SSP */
		bts_ssp {
			reg = <0x0 0x1A8E0000 0x100>;
			status = "okay";
			bts-type = <IP_BTS>;
			default {
				stat_on = <1>;
				bypass = <0>;
				arqos = <0x4>;
				awqos = <0x4>;
				rmo = <0x4>;
				wmo = <0x4>;
				qurgent_on = <0>;
				blocking_on = <0>;
			};
		};
		/* NOCL0 UFD */
		bts_ufd {
			reg = <0x0 0x1A8F0000 0x100>;
			status = "okay";
			bts-type = <IP_BTS>;
			default {
				stat_on = <1>;
				bypass = <0>;
				arqos = <0x4>;
				awqos = <0x4>;
				rmo = <0x4>;
				wmo = <0x4>;
				qurgent_on = <0>;
				blocking_on = <0>;
			};
		};
		/* NOCL0 G_CSSYS */
		bts_cssys {
			reg = <0x0 0x1A880000 0x100>;
			status = "okay";
			bts-type = <IP_BTS>;
			default {
				stat_on = <1>;
				bypass = <0>;
				arqos = <0x4>;
				awqos = <0x4>;
				rmo = <0x4>;
				wmo = <0x4>;
				qurgent_on = <0>;
				blocking_on = <0>;
			};
		};
		/* NOCL0 D1_MODEM */
		bts_d1modem {
			reg = <0x0 0x1A8A0000 0x100>;
			status = "okay";
			bts-type = <IP_BTS>;
			default {
				stat_on = <1>;
				bypass = <1>;
				rmo = <0x14>;
				wmo = <0x14>;
				qurgent_on = <0>;
				blocking_on = <0>;
			};
		};
		/* NOCL0 D2_MODEM */
		bts_d2modem {
			reg = <0x0 0x1A8B0000 0x100>;
			status = "okay";
			bts-type = <IP_BTS>;
			default {
				stat_on = <1>;
				bypass = <0>;
				arqos = <0x4>;
				awqos = <0x4>;
				rmo = <0x14>;
				wmo = <0x8>;
				qurgent_on = <0>;
				blocking_on = <0>;
			};
		};
		/* D_DNC */
		bts_dnc0 {
			reg = <0x0 0x1BE00000 0x100>;
			status = "okay";
			bts-type = <IP_BTS>;
			cal-pdid = <0xB1380015>;
			default {
				stat_on = <1>;
				bypass = <0>;
				arqos = <0x4>;
				awqos = <0x4>;
				rmo = <0xC>;
				wmo = <0xC>;
				qurgent_on = <0>;
				blocking_on = <0>;
			};
			camera_default {
				stat_on = <1>;
				bypass = <0>;
				arqos = <0x4>;
				awqos = <0x4>;
				rmo = <0x30>;
				wmo = <0x30>;
				qurgent_on = <0>;
				blocking_on = <0>;
			};
			npu_normal {
				stat_on = <1>;
				bypass = <0>;
				arqos = <0x4>;
				awqos = <0x4>;
				rmo = <0x30>;
				wmo = <0x30>;
				qurgent_on = <0>;
				blocking_on = <0>;
			};
			camera_heavy {
				stat_on = <1>;
				bypass = <0>;
				arqos = <0x4>;
				awqos = <0x4>;
				rmo = <0x30>;
				wmo = <0x30>;
				qurgent_on = <0>;
				blocking_on = <0>;
			};
			npu_performance {
				stat_on = <1>;
				bypass = <0>;
				arqos = <0x4>;
				awqos = <0x4>;
				rmo = <0xFFFF>;
				wmo = <0xFFFF>;
				qurgent_on = <0>;
				blocking_on = <0>;
			};
		};
		/* D_DNC */
		bts_dnc1 {
			reg = <0x0 0x1BE10000 0x100>;
			status = "okay";
			bts-type = <IP_BTS>;
			cal-pdid = <0xB1380015>;
			default {
				stat_on = <1>;
				bypass = <0>;
				arqos = <0x4>;
				awqos = <0x4>;
				rmo = <0xC>;
				wmo = <0xC>;
				qurgent_on = <0>;
				blocking_on = <0>;
			};
			camera_default {
				stat_on = <1>;
				bypass = <0>;
				arqos = <0x4>;
				awqos = <0x4>;
				rmo = <0x30>;
				wmo = <0x30>;
				qurgent_on = <0>;
				blocking_on = <0>;
			};
			npu_normal {
				stat_on = <1>;
				bypass = <0>;
				arqos = <0x4>;
				awqos = <0x4>;
				rmo = <0x30>;
				wmo = <0x30>;
				qurgent_on = <0>;
				blocking_on = <0>;
			};
			camera_heavy {
				stat_on = <1>;
				bypass = <0>;
				arqos = <0x4>;
				awqos = <0x4>;
				rmo = <0x30>;
				wmo = <0x30>;
				qurgent_on = <0>;
				blocking_on = <0>;
			};
			npu_performance {
				stat_on = <1>;
				bypass = <0>;
				arqos = <0x4>;
				awqos = <0x4>;
				rmo = <0xFFFF>;
				wmo = <0xFFFF>;
				qurgent_on = <0>;
				blocking_on = <0>;
			};
		};
		/* D_DNC */
		bts_dnc2 {
			reg = <0x0 0x1BE20000 0x100>;
			status = "okay";
			bts-type = <IP_BTS>;
			cal-pdid = <0xB1380015>;
			default {
				stat_on = <1>;
				bypass = <0>;
				arqos = <0x4>;
				awqos = <0x4>;
				rmo = <0xC>;
				wmo = <0xC>;
				qurgent_on = <0>;
				blocking_on = <0>;
			};
			camera_default {
				stat_on = <1>;
				bypass = <0>;
				arqos = <0x4>;
				awqos = <0x4>;
				rmo = <0x30>;
				wmo = <0x30>;
				qurgent_on = <0>;
				blocking_on = <0>;
			};
			npu_normal {
				stat_on = <1>;
				bypass = <0>;
				arqos = <0x4>;
				awqos = <0x4>;
				rmo = <0x30>;
				wmo = <0x30>;
				qurgent_on = <0>;
				blocking_on = <0>;
			};
			camera_heavy {
				stat_on = <1>;
				bypass = <0>;
				arqos = <0x4>;
				awqos = <0x4>;
				rmo = <0x30>;
				wmo = <0x30>;
				qurgent_on = <0>;
				blocking_on = <0>;
			};
			npu_performance {
				stat_on = <1>;
				bypass = <0>;
				arqos = <0x4>;
				awqos = <0x4>;
				rmo = <0xFFFF>;
				wmo = <0xFFFF>;
				qurgent_on = <0>;
				blocking_on = <0>;
			};
		};
		/* D_DNC */
		bts_dnc3 {
			reg = <0x0 0x1BE30000 0x100>;
			status = "okay";
			bts-type = <IP_BTS>;
			cal-pdid = <0xB1380015>;
			default {
				stat_on = <1>;
				bypass = <0>;
				arqos = <0x4>;
				awqos = <0x4>;
				rmo = <0xC>;
				wmo = <0xC>;
				qurgent_on = <0>;
				blocking_on = <0>;
			};
			camera_default {
				stat_on = <1>;
				bypass = <0>;
				arqos = <0x4>;
				awqos = <0x4>;
				rmo = <0x30>;
				wmo = <0x30>;
				qurgent_on = <0>;
				blocking_on = <0>;
			};
			npu_normal {
				stat_on = <1>;
				bypass = <0>;
				arqos = <0x4>;
				awqos = <0x4>;
				rmo = <0x30>;
				wmo = <0x30>;
				qurgent_on = <0>;
				blocking_on = <0>;
			};
			camera_heavy {
				stat_on = <1>;
				bypass = <0>;
				arqos = <0x4>;
				awqos = <0x4>;
				rmo = <0x30>;
				wmo = <0x30>;
				qurgent_on = <0>;
				blocking_on = <0>;
			};
			npu_performance {
				stat_on = <1>;
				bypass = <0>;
				arqos = <0x4>;
				awqos = <0x4>;
				rmo = <0xFFFF>;
				wmo = <0xFFFF>;
				qurgent_on = <0>;
				blocking_on = <0>;
			};
		};
		/* D_DNC */
		bts_dnc4 {
			reg = <0x0 0x1BE40000 0x100>;
			status = "okay";
			bts-type = <IP_BTS>;
			cal-pdid = <0xB1380015>;
			default {
				stat_on = <1>;
				bypass = <0>;
				arqos = <0x4>;
				awqos = <0x4>;
				rmo = <0xC>;
				wmo = <0xC>;
				qurgent_on = <0>;
				blocking_on = <0>;
			};
			camera_default {
				stat_on = <1>;
				bypass = <0>;
				arqos = <0x4>;
				awqos = <0x4>;
				rmo = <0x30>;
				wmo = <0x30>;
				qurgent_on = <0>;
				blocking_on = <0>;
			};
			npu_normal {
				stat_on = <1>;
				bypass = <0>;
				arqos = <0x4>;
				awqos = <0x4>;
				rmo = <0x30>;
				wmo = <0x30>;
				qurgent_on = <0>;
				blocking_on = <0>;
			};
			camera_heavy {
				stat_on = <1>;
				bypass = <0>;
				arqos = <0x4>;
				awqos = <0x4>;
				rmo = <0x30>;
				wmo = <0x30>;
				qurgent_on = <0>;
				blocking_on = <0>;
			};
			npu_performance {
				stat_on = <1>;
				bypass = <0>;
				arqos = <0x4>;
				awqos = <0x4>;
				rmo = <0xFFFF>;
				wmo = <0xFFFF>;
				qurgent_on = <0>;
				blocking_on = <0>;
			};
		};
	};
};
